# STM32F105 register map
File version: 1.3
CPU: CM3 r1p1, little endian, no MPU, no FPU, 4 interrupt priority bits
Registers are 32-bit, read-write, reset 0x0 unless marked. A register's access mark holds for its fields unless they carry their own. Offsets are from the block's base; [hi:lo] are bit positions; {n}, {i} and the like mark numbered series.

## EXTI
Base 0x40010400
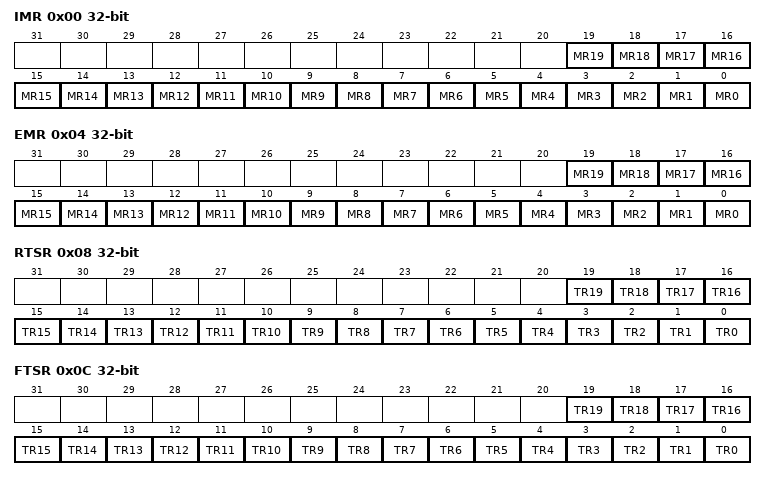
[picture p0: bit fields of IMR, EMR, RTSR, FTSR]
0x00 IMR — Interrupt mask register (EXTI_IMR)
  [n] MR{n} (n=0..19) — Interrupt Mask on line {n}
0x04 EMR — Event mask register (EXTI_EMR)
  [n] MR{n} (n=0..19) — Event Mask on line {n}
0x08 RTSR — Rising Trigger selection register (EXTI_RTSR)
  [n] TR{n} (n=0..19) — Rising trigger event configuration of line {n}
0x0C FTSR — Falling Trigger selection register (EXTI_FTSR)
  [n] TR{n} (n=0..19) — Falling trigger event configuration of line {n}
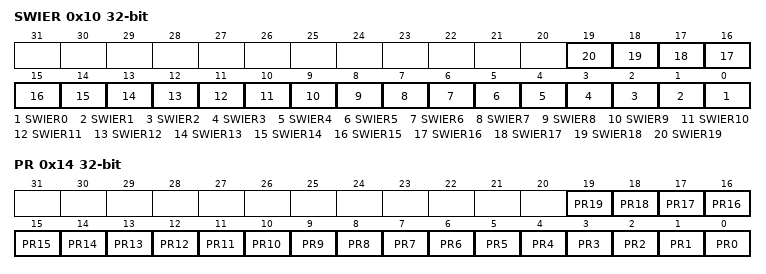
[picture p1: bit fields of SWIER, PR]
0x10 SWIER — Software interrupt event register (EXTI_SWIER)
  [n] SWIER{n} (n=0..19) — Software Interrupt on line {n}
0x14 PR — Pending register (EXTI_PR)
  [n] PR{n} (n=0..19) — Pending bit {n}

## FLASH
Base 0x40022000
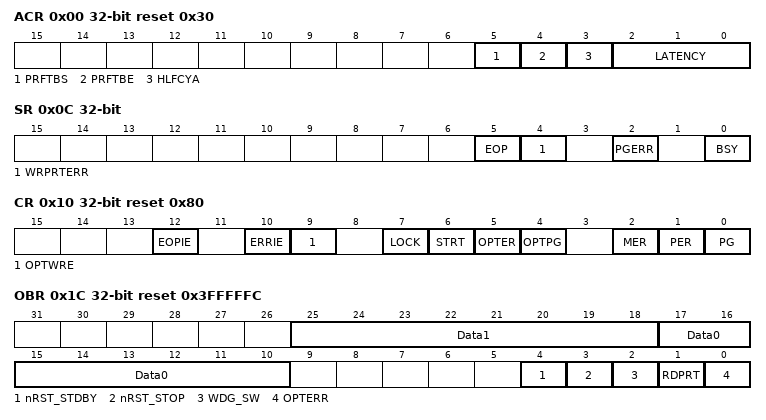
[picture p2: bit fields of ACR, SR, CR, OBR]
0x00 ACR access per field reset 0x30 — Flash access control register
  [5] PRFTBS ro — Prefetch buffer status
  [4] PRFTBE rw — Prefetch buffer enable
  [3] HLFCYA rw — Flash half cycle access enable
  [2:0] LATENCY rw
0x04 KEYR wo — Flash key register
  [31:0] KEY — FPEC key
0x08 OPTKEYR wo — Flash option key register
  [31:0] OPTKEY — Option byte key
0x0C SR access per field — Status register
  [5] EOP rw — End of operation
  [4] WRPRTERR rw — Write protection error
  [2] PGERR rw — Programming error
  [0] BSY ro — Busy
0x10 CR reset 0x80 — Control register
  [12] EOPIE — End of operation interrupt enable
  [10] ERRIE — Error interrupt enable
  [9] OPTWRE — Option bytes write enable
  [7] LOCK
  [6] STRT — Start
  [5] OPTER — Option byte erase
  [4] OPTPG — Option byte programming
  [2] MER — Mass Erase
  [1] PER — Page Erase
  [0] PG — Programming
0x14 AR wo — Flash address register
  [31:0] FAR — Flash Address
0x1C OBR ro reset 0x3FFFFFC — Option byte register
  [25:18] Data1
  [17:10] Data0
  [4] nRST_STDBY
  [3] nRST_STOP
  [2] WDG_SW
  [1] RDPRT — Read protection
  [0] OPTERR — Option byte error
0x20 WRPR ro reset 0xFFFFFFFF — Write protection register
  [31:0] WRP — Write protect

## GPIOA — General purpose I/O
Base 0x40010800
Same registers: GPIOB 0x40010C00, GPIOC 0x40011000, GPIOD 0x40011400, GPIOE 0x40011800, GPIOF 0x40011C00, GPIOG 0x40012000
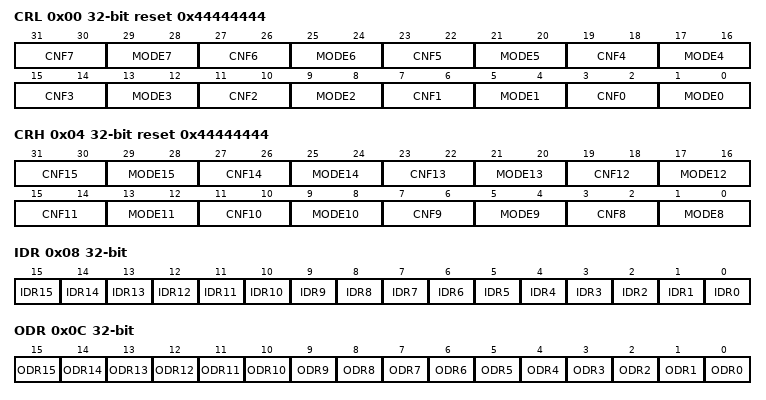
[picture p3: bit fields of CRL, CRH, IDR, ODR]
0x00 CRL reset 0x44444444 — Port configuration register low (GPIOn_CRL)
  [31:30] CNF7 — Port n.7 configuration bits
  [29:28] MODE7 — Port n.7 mode bits
  [27:26] CNF6 — Port n.6 configuration bits
  [25:24] MODE6 — Port n.6 mode bits
  [23:22] CNF5 — Port n.5 configuration bits
  [21:20] MODE5 — Port n.5 mode bits
  [19:18] CNF4 — Port n.4 configuration bits
  [17:16] MODE4 — Port n.4 mode bits
  [15:14] CNF3 — Port n.3 configuration bits
  [13:12] MODE3 — Port n.3 mode bits
  [11:10] CNF2 — Port n.2 configuration bits
  [9:8] MODE2 — Port n.2 mode bits
  [7:6] CNF1 — Port n.1 configuration bits
  [5:4] MODE1 — Port n.1 mode bits
  [3:2] CNF0 — Port n.0 configuration bits
  [1:0] MODE0 — Port n.0 mode bits
0x04 CRH reset 0x44444444 — Port configuration register high (GPIOn_CRL)
  [31:30] CNF15 — Port n.15 configuration bits
  [29:28] MODE15 — Port n.15 mode bits
  [27:26] CNF14 — Port n.14 configuration bits
  [25:24] MODE14 — Port n.14 mode bits
  [23:22] CNF13 — Port n.13 configuration bits
  [21:20] MODE13 — Port n.13 mode bits
  [19:18] CNF12 — Port n.12 configuration bits
  [17:16] MODE12 — Port n.12 mode bits
  [15:14] CNF11 — Port n.11 configuration bits
  [13:12] MODE11 — Port n.11 mode bits
  [11:10] CNF10 — Port n.10 configuration bits
  [9:8] MODE10 — Port n.10 mode bits
  [7:6] CNF9 — Port n.9 configuration bits
  [5:4] MODE9 — Port n.9 mode bits
  [3:2] CNF8 — Port n.8 configuration bits
  [1:0] MODE8 — Port n.8 mode bits
0x08 IDR ro — Port input data register (GPIOn_IDR)
  [n] IDR{n} (n=0..15) — Port input data
0x0C ODR — Port output data register (GPIOn_ODR)
  [n] ODR{n} (n=0..15) — Port output data
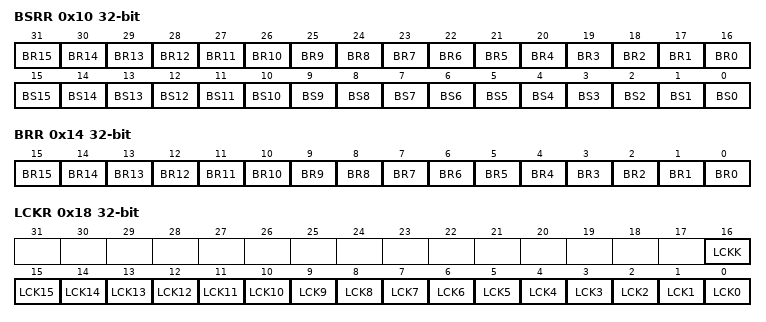
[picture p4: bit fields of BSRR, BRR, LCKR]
0x10 BSRR wo — Port bit set/reset register (GPIOn_BSRR)
  [n+16] BR{n} (n=0..15) — Reset bit {n}
  [n] BS{n} (n=3..15) — Set bit {n}
  [2] BS2 — Set bit 1
  [1] BS1 — Set bit 1
  [0] BS0 — Set bit 0
0x14 BRR wo — Port bit reset register (GPIOn_BRR)
  [n] BR{n} (n=3..15) — Reset bit {n}
  [2] BR2 — Reset bit 1
  [1] BR1 — Reset bit 1
  [0] BR0 — Reset bit 0
0x18 LCKR — Port configuration lock register
  [16] LCKK — Lock key
  [n] LCK{n} (n=0..15) — Port A Lock bit {n}
